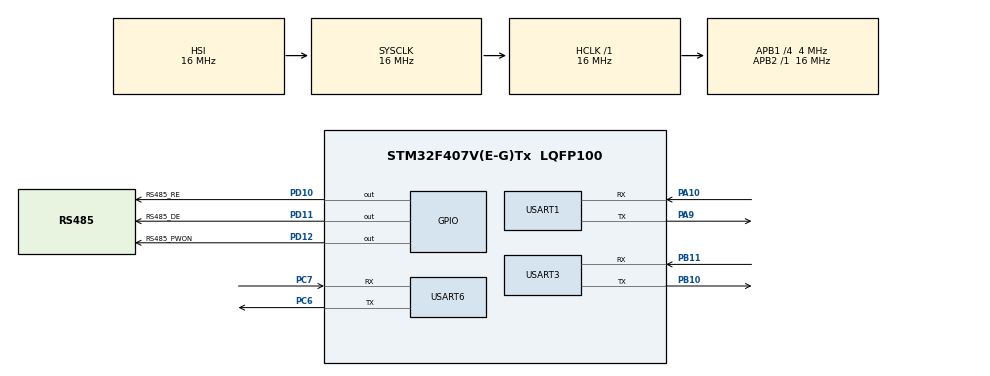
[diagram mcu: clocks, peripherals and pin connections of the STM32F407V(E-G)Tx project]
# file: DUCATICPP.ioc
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Dma.Request0=USART6_RX
Dma.Request1=USART1_RX
Dma.Request2=USART3_RX
Dma.USART1_RX.1.Direction=DMA_PERIPH_TO_MEMORY
Dma.USART1_RX.1.FIFOMode=DMA_FIFOMODE_DISABLE
Dma.USART1_RX.1.Instance=DMA2_Stream2
Dma.USART1_RX.1.MemDataAlignment=DMA_MDATAALIGN_BYTE
Dma.USART1_RX.1.MemInc=DMA_MINC_ENABLE
Dma.USART1_RX.1.Mode=DMA_NORMAL
Dma.USART1_RX.1.PeriphDataAlignment=DMA_PDATAALIGN_BYTE
Dma.USART1_RX.1.PeriphInc=DMA_PINC_DISABLE
Dma.USART1_RX.1.Priority=DMA_PRIORITY_LOW
Dma.USART3_RX.2.Direction=DMA_PERIPH_TO_MEMORY
Dma.USART3_RX.2.FIFOMode=DMA_FIFOMODE_DISABLE
Dma.USART3_RX.2.Instance=DMA1_Stream1
Dma.USART3_RX.2.MemDataAlignment=DMA_MDATAALIGN_BYTE
Dma.USART3_RX.2.MemInc=DMA_MINC_ENABLE
Dma.USART3_RX.2.Mode=DMA_NORMAL
Dma.USART3_RX.2.PeriphDataAlignment=DMA_PDATAALIGN_BYTE
Dma.USART3_RX.2.PeriphInc=DMA_PINC_DISABLE
Dma.USART3_RX.2.Priority=DMA_PRIORITY_LOW
Dma.USART6_RX.0.Direction=DMA_PERIPH_TO_MEMORY
Dma.USART6_RX.0.FIFOMode=DMA_FIFOMODE_DISABLE
Dma.USART6_RX.0.Instance=DMA2_Stream1
Dma.USART6_RX.0.MemDataAlignment=DMA_MDATAALIGN_BYTE
Dma.USART6_RX.0.MemInc=DMA_MINC_ENABLE
Dma.USART6_RX.0.Mode=DMA_NORMAL
Dma.USART6_RX.0.PeriphDataAlignment=DMA_PDATAALIGN_BYTE
Dma.USART6_RX.0.PeriphInc=DMA_PINC_DISABLE
Dma.USART6_RX.0.Priority=DMA_PRIORITY_LOW
Mcu.Family=STM32F4
Mcu.Name=STM32F407V(E-G)Tx
Mcu.Package=LQFP100
NVIC.DMA1_Stream1_IRQn=true\:0\:0\:false\:false\:true\:false\:true\:true
NVIC.DMA2_Stream1_IRQn=true\:0\:0\:false\:false\:true\:false\:true\:true
NVIC.DMA2_Stream2_IRQn=true\:0\:0\:false\:false\:true\:false\:true\:true
NVIC.PriorityGroup=NVIC_PRIORITYGROUP_4
NVIC.USART1_IRQn=true\:0\:0\:false\:false\:true\:true\:true\:true
NVIC.USART3_IRQn=true\:0\:0\:false\:false\:true\:true\:true\:true
NVIC.USART6_IRQn=true\:0\:0\:false\:false\:true\:true\:true\:true
PA10.Mode=Asynchronous
PA10.Signal=USART1_RX
PA13.Mode=Serial_Wire
PA13.Signal=SYS_JTMS-SWDIO
PA14.Mode=Serial_Wire
PA14.Signal=SYS_JTCK-SWCLK
PA9.Mode=Asynchronous
PA9.Signal=USART1_TX
PB10.Mode=Asynchronous
PB10.Signal=USART3_TX
PB11.Mode=Asynchronous
PB11.Signal=USART3_RX
PC6.Mode=Asynchronous
PC6.Signal=USART6_TX
PC7.Mode=Asynchronous
PC7.Signal=USART6_RX
PD10.GPIO_Label=RS485_RE
PD10.Signal=GPIO_Output
PD11.GPIO_Label=RS485_DE
PD11.Signal=GPIO_Output
PD12.GPIO_Label=RS485_PWON
PD12.Signal=GPIO_Output
ProjectManager.HeapSize=0x200
ProjectManager.StackSize=0x400
ProjectManager.TargetToolchain=STM32CubeIDE
RCC.48MHZClocksFreq_Value=48000000
RCC.AHBFreq_Value=16000000
RCC.APB1CLKDivider=RCC_HCLK_DIV4
RCC.APB1Freq_Value=4000000
RCC.APB1TimFreq_Value=8000000
RCC.APB2Freq_Value=16000000
RCC.APB2TimFreq_Value=16000000
RCC.CortexFreq_Value=16000000
RCC.HCLKFreq_Value=16000000
RCC.HSE_VALUE=25000000
RCC.HSI_VALUE=16000000
RCC.SYSCLKFreq_VALUE=16000000
RCC.VCOOutputFreq_Value=192000000
USART1.VirtualMode=VM_ASYNC
USART3.VirtualMode=VM_ASYNC
USART6.VirtualMode=VM_ASYNC
board=custom

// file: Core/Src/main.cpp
/* USER CODE BEGIN Header */
/**
 ******************************************************************************
 * @file           : main.c
 * @brief          : Main program body
 ******************************************************************************
 * @attention
 *
 * Copyright (c) 2024 STMicroelectronics.
 * All rights reserved.
 *
 * This software is licensed under terms that can be found in the LICENSE file
 * in the root directory of this software component.
 * If no LICENSE file comes with this software, it is provided AS-IS.
 *
 ******************************************************************************
 */
/* USER CODE END Header */
#include "main.h"

/* USER CODE BEGIN Includes */
#include "interface.h"
/* USER CODE END Includes */

/* USER CODE BEGIN PD */
void HAL_UARTEx_RxEventCallback(UART_HandleTypeDef *huart, uint16_t Size) {
	if (huart->Instance == USART1) {
		pulsar::getInstance()->SET_FLAG();
		pulsar::getInstance()->Get_size(Size);
	}
}
/* USER CODE END PD */

UART_HandleTypeDef huart1;
UART_HandleTypeDef huart3;
UART_HandleTypeDef huart6;
DMA_HandleTypeDef hdma_usart1_rx;
DMA_HandleTypeDef hdma_usart3_rx;
DMA_HandleTypeDef hdma_usart6_rx;

void SystemClock_Config(void);
static void MX_GPIO_Init(void);
static void MX_DMA_Init(void);
static void MX_USART1_UART_Init(void);
static void MX_USART6_UART_Init(void);
static void MX_USART3_UART_Init(void);

int main(void)
{

  /* MCU Configuration--------------------------------------------------------*/

  /* Reset of all peripherals, Initializes the Flash interface and the Systick. */
  HAL_Init();

  /* Configure the system clock */
  SystemClock_Config();

  /* Initialize all configured peripherals */
  MX_GPIO_Init();
  MX_DMA_Init();
  MX_USART1_UART_Init();
  MX_USART6_UART_Init();
  MX_USART3_UART_Init();
  /* USER CODE BEGIN 2 */
	pulsar::getInstance()->modbusOnPower();
	interface::getInstance()->initMain();
  /* USER CODE END 2 */

  /* Infinite loop */
	while (1) {

    /* USER CODE BEGIN 3 */
		pulsar::getInstance()->getFirmwareID();
	}
  /* USER CODE END 3 */
}

void SystemClock_Config(void)
{
  RCC_OscInitTypeDef RCC_OscInitStruct = {0};
  RCC_ClkInitTypeDef RCC_ClkInitStruct = {0};

  /** Configure the main internal regulator output voltage
  */
  __HAL_RCC_PWR_CLK_ENABLE();
  __HAL_PWR_VOLTAGESCALING_CONFIG(PWR_REGULATOR_VOLTAGE_SCALE1);

  /** Initializes the RCC Oscillators according to the specified parameters
  * in the RCC_OscInitTypeDef structure.
  */
  RCC_OscInitStruct.OscillatorType = RCC_OSCILLATORTYPE_HSI;
  RCC_OscInitStruct.HSIState = RCC_HSI_ON;
  RCC_OscInitStruct.HSICalibrationValue = RCC_HSICALIBRATION_DEFAULT;
  RCC_OscInitStruct.PLL.PLLState = RCC_PLL_NONE;
  if (HAL_RCC_OscConfig(&RCC_OscInitStruct) != HAL_OK)
  {
    Error_Handler();
  }

  /** Initializes the CPU, AHB and APB buses clocks
  */
  RCC_ClkInitStruct.ClockType = RCC_CLOCKTYPE_HCLK|RCC_CLOCKTYPE_SYSCLK
                              |RCC_CLOCKTYPE_PCLK1|RCC_CLOCKTYPE_PCLK2;
  RCC_ClkInitStruct.SYSCLKSource = RCC_SYSCLKSOURCE_HSI;
  RCC_ClkInitStruct.AHBCLKDivider = RCC_SYSCLK_DIV1;
  RCC_ClkInitStruct.APB1CLKDivider = RCC_HCLK_DIV4;
  RCC_ClkInitStruct.APB2CLKDivider = RCC_HCLK_DIV1;

  if (HAL_RCC_ClockConfig(&RCC_ClkInitStruct, FLASH_LATENCY_0) != HAL_OK)
  {
    Error_Handler();
  }
}

static void MX_USART1_UART_Init(void)
{

  huart1.Instance = USART1;
  huart1.Init.BaudRate = 115200;
  huart1.Init.WordLength = UART_WORDLENGTH_8B;
  huart1.Init.StopBits = UART_STOPBITS_1;
  huart1.Init.Parity = UART_PARITY_NONE;
  huart1.Init.Mode = UART_MODE_TX_RX;
  huart1.Init.HwFlowCtl = UART_HWCONTROL_NONE;
  huart1.Init.OverSampling = UART_OVERSAMPLING_16;
  if (HAL_UART_Init(&huart1) != HAL_OK)
  {
    Error_Handler();
  }

}

static void MX_USART3_UART_Init(void)
{

  huart3.Instance = USART3;
  huart3.Init.BaudRate = 115200;
  huart3.Init.WordLength = UART_WORDLENGTH_8B;
  huart3.Init.StopBits = UART_STOPBITS_1;
  huart3.Init.Parity = UART_PARITY_NONE;
  huart3.Init.Mode = UART_MODE_TX_RX;
  huart3.Init.HwFlowCtl = UART_HWCONTROL_NONE;
  huart3.Init.OverSampling = UART_OVERSAMPLING_16;
  if (HAL_UART_Init(&huart3) != HAL_OK)
  {
    Error_Handler();
  }

}

static void MX_USART6_UART_Init(void)
{

  huart6.Instance = USART6;
  huart6.Init.BaudRate = 115200;
  huart6.Init.WordLength = UART_WORDLENGTH_8B;
  huart6.Init.StopBits = UART_STOPBITS_1;
  huart6.Init.Parity = UART_PARITY_NONE;
  huart6.Init.Mode = UART_MODE_TX_RX;
  huart6.Init.HwFlowCtl = UART_HWCONTROL_NONE;
  huart6.Init.OverSampling = UART_OVERSAMPLING_16;
  if (HAL_UART_Init(&huart6) != HAL_OK)
  {
    Error_Handler();
  }

}

static void MX_DMA_Init(void)
{

  /* DMA controller clock enable */
  __HAL_RCC_DMA2_CLK_ENABLE();
  __HAL_RCC_DMA1_CLK_ENABLE();

  /* DMA interrupt init */
  /* DMA1_Stream1_IRQn interrupt configuration */
  HAL_NVIC_SetPriority(DMA1_Stream1_IRQn, 0, 0);
  HAL_NVIC_EnableIRQ(DMA1_Stream1_IRQn);
  /* DMA2_Stream1_IRQn interrupt configuration */
  HAL_NVIC_SetPriority(DMA2_Stream1_IRQn, 0, 0);
  HAL_NVIC_EnableIRQ(DMA2_Stream1_IRQn);
  /* DMA2_Stream2_IRQn interrupt configuration */
  HAL_NVIC_SetPriority(DMA2_Stream2_IRQn, 0, 0);
  HAL_NVIC_EnableIRQ(DMA2_Stream2_IRQn);

}

static void MX_GPIO_Init(void)
{
  GPIO_InitTypeDef GPIO_InitStruct = {0};

  /* GPIO Ports Clock Enable */
  __HAL_RCC_GPIOB_CLK_ENABLE();
  __HAL_RCC_GPIOD_CLK_ENABLE();
  __HAL_RCC_GPIOC_CLK_ENABLE();
  __HAL_RCC_GPIOA_CLK_ENABLE();

  /*Configure GPIO pin Output Level */
  HAL_GPIO_WritePin(GPIOD, RS485_RE_Pin|RS485_DE_Pin|RS485_PWON_Pin, GPIO_PIN_RESET);

  /*Configure GPIO pins : RS485_RE_Pin RS485_DE_Pin RS485_PWON_Pin */
  GPIO_InitStruct.Pin = RS485_RE_Pin|RS485_DE_Pin|RS485_PWON_Pin;
  GPIO_InitStruct.Mode = GPIO_MODE_OUTPUT_PP;
  GPIO_InitStruct.Pull = GPIO_NOPULL;
  GPIO_InitStruct.Speed = GPIO_SPEED_FREQ_LOW;
  HAL_GPIO_Init(GPIOD, &GPIO_InitStruct);

}

void Error_Handler(void)
{
	__disable_irq();
	while (1) {
	}
}
